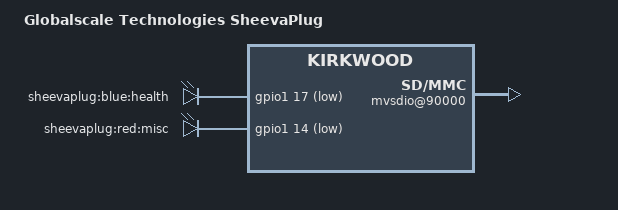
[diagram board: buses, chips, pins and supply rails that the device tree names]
/dts-v1/;
#include "kirkwood-sheevaplug-common.dtsi"
/ {
	model = "Globalscale Technologies SheevaPlug";
	compatible = "globalscale,sheevaplug", "marvell,kirkwood-88f6281", "marvell,kirkwood";
	ocp@f1000000 {
		mvsdio@90000 {
			pinctrl-0 = <&pmx_sdio>;
			pinctrl-names = "default";
			status = "okay";
			broken-cd;
		};
	};
	gpio-leds {
		compatible = "gpio-leds";
		pinctrl-0 = <&pmx_led_blue &pmx_led_red>;
		pinctrl-names = "default";
		health {
			label = "sheevaplug:blue:health";
			gpios = <&gpio1 17 GPIO_ACTIVE_LOW>;
			default-state = "keep";
		};
		misc {
			label = "sheevaplug:red:misc";
			gpios = <&gpio1 14 GPIO_ACTIVE_LOW>;
		};
	};
};
